VERSION ""

NS_ :

BS_:

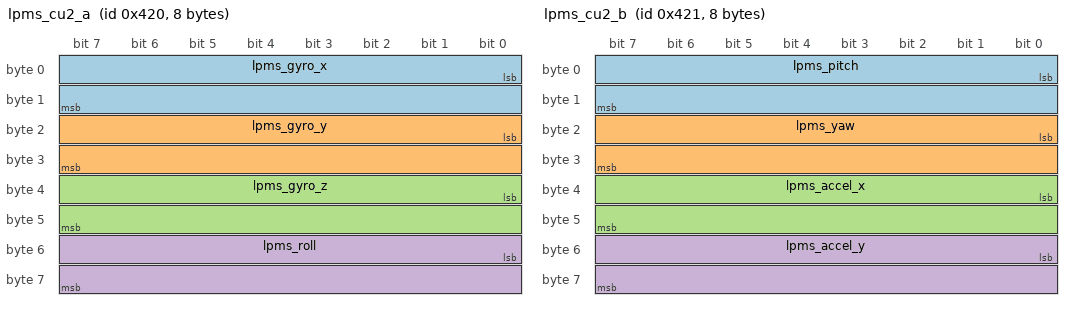
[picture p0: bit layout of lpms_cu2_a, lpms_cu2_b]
BO_ 1056 lpms_cu2_a: 8 IVT_Mod
 SG_ lpms_gyro_x :	 0|16@1- (0.001,0) 	[-2000|2000] "deg/s"  Vector__XXX
 SG_ lpms_gyro_y :	16|16@1- (0.001,0) 	[-2000|2000] "deg/s"  Vector__XXX
 SG_ lpms_gyro_z :	32|16@1- (0.001,0) 	[-2000|2000] "deg/s"  Vector__XXX
 SG_ lpms_roll :	48|16@1- (0.00573,0) 	[-180|180] "deg"  Vector__XXX

BO_ 1057 lpms_cu2_b: 8 IVT_Mod
 SG_ lpms_pitch :	 0|16@1- (0.00573,0) 	[-180|180] "deg"  Vector__XXX
 SG_ lpms_yaw :		16|16@1- (0.00573,0) 	[-180|180] "deg"  Vector__XXX
 SG_ lpms_accel_x : 	32|16@1- (0.001,0) 	[-8|8] "g"  Vector__XXX
 SG_ lpms_accel_y : 	48|16@1- (0.001,0) 	[-8|8] "g"  Vector__XXX

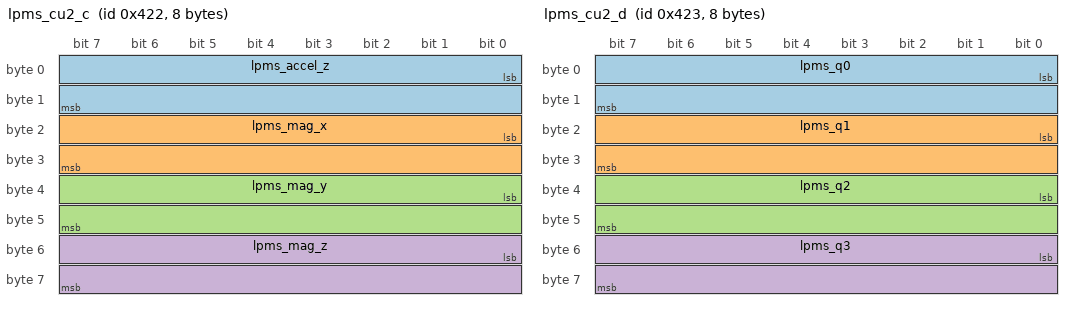
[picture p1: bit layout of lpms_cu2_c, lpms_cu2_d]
BO_ 1058 lpms_cu2_c: 8 IVT_Mod
 SG_ lpms_accel_z : 	 0|16@1- (0.001,0) 	[-8|8] "g"  Vector__XXX
 SG_ lpms_mag_x	: 	16|16@1- (0.01,0) 	[-8|8] "uT"  Vector__XXX
 SG_ lpms_mag_y : 	32|16@1- (0.01,0) 	[-8|8] "uT"  Vector__XXX
 SG_ lpms_mag_z : 	48|16@1- (0.01,0) 	[-8|8] "uT"  Vector__XXX

BO_ 1059 lpms_cu2_d: 8 IVT_Mod
 SG_ lpms_q0 : 		 0|16@1- (0.0001,0) 	[-1|1] ""  Vector__XXX
 SG_ lpms_q1 : 		16|16@1- (0.0001,0) 	[-1|1] ""  Vector__XXX
 SG_ lpms_q2 : 		32|16@1- (0.0001,0) 	[-1|1] ""  Vector__XXX
 SG_ lpms_q3 : 		48|16@1- (0.0001,0) 	[-1|1] ""  Vector__XXX
